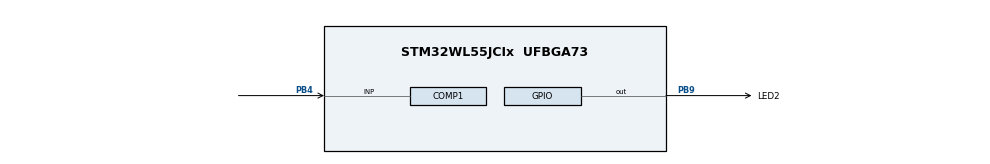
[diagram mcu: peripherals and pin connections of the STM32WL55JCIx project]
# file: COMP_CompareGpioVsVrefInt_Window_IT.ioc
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COMP1.BlankingSrce=COMP_BLANKINGSRC_NONE
COMP1.Hysteresis=COMP_HYSTERESIS_NONE
COMP1.Mode=COMP_POWERMODE_MEDIUMSPEED
COMP1.OutputPol=COMP_OUTPUTPOL_NONINVERTED
COMP1.TriggerMode=COMP_TRIGGERMODE_IT_RISING_FALLING
COMP2.BlankingSrce=COMP_BLANKINGSRC_NONE
COMP2.Hysteresis=COMP_HYSTERESIS_LOW
COMP2.Mode=COMP_POWERMODE_MEDIUMSPEED
COMP2.OutputPol=COMP_OUTPUTPOL_NONINVERTED
COMP2.TriggerMode=COMP_TRIGGERMODE_IT_RISING_FALLING
COMP2.WindowMode=COMP_WINDOWMODE_COMP1_INPUT_PLUS_COMMON
Mcu.Family=STM32WL
Mcu.Name=STM32WL55JCIx
Mcu.Package=UFBGA73
NVIC.COMP_IRQn=true\:0\:0\:false\:false\:true\:false\:true
NVIC.PriorityGroup=NVIC_PRIORITYGROUP_4
PB4.Mode=INP
PB4.Signal=COMP1_INP
PB9.GPIO_Label=LED2
PB9.Signal=GPIO_Output
ProjectManager.HeapSize=0x200
ProjectManager.StackSize=0x400
ProjectManager.TargetToolchain=EWARM V8
RCC.AHBFreq_Value=48000000
RCC.APB1Freq_Value=48000000
RCC.APB1TimFreq_Value=48000000
RCC.APB2Freq_Value=48000000
RCC.APB2TimFreq_Value=48000000
RCC.APB3Freq_Value=48000000
RCC.CortexFreq_Value=48000000
RCC.HCLKFreq_Value=48000000
RCC.HSE_VALUE=8000000
RCC.HSI_VALUE=16000000
RCC.LSE_VALUE=32768
RCC.MSIClockRange=RCC_MSIRANGE_11
RCC.SYSCLKFreq_VALUE=48000000
RCC.VCOOutputFreq_Value=384000000
VP_COMP1_VS_VREFINT.Mode=VREFINT
VP_COMP2_VS_VREFINT12.Mode=VREFINT_12
VP_COMP2_VS_WindowMode.Mode=WindowMode
board=custom

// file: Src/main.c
/* USER CODE BEGIN Header */
/**
  ******************************************************************************
  * @file    COMP/COMP_CompareGpioVsVrefInt_Window_IT/Src/main.c
  * @author  MCD Application Team
  * @brief   This example describes how to use a pair of comparator peripherals
  *          to compare a voltage level applied on a GPIO pin
  *          versus 2 thresholds, in interrupt mode.
  ******************************************************************************
  * @attention
  *
  * <h2><center>&copy; Copyright (c) 2020 STMicroelectronics.
  * All rights reserved.</center></h2>
  *
  * This software component is licensed by ST under BSD 3-Clause license,
  * the "License"; You may not use this file except in compliance with the
  * License. You may obtain a copy of the License at:
  *                        opensource.org/licenses/BSD-3-Clause
  *
  ******************************************************************************
  */
/* USER CODE END Header */
#include "main.h"

COMP_HandleTypeDef hcomp1;
COMP_HandleTypeDef hcomp2;

void SystemClock_Config(void);
static void MX_GPIO_Init(void);
static void MX_COMP1_Init(void);
static void MX_COMP2_Init(void);

int main(void)
{

  /* MCU Configuration--------------------------------------------------------*/

  /* Reset of all peripherals, Initializes the Flash interface and the Systick. */
  HAL_Init();

  /* Configure the system clock */
  SystemClock_Config();

  /* Initialize all configured peripherals */
  MX_GPIO_Init();
  MX_COMP1_Init();
  MX_COMP2_Init();
  /* USER CODE BEGIN 2 */

  /* Activate pair of comparators */
  /* Enable comparator instance master */
  if(HAL_COMP_Start(&hcomp1) != HAL_OK)
  {
    /* Initialization Error */
    Error_Handler();
  }
  /* Enable comparator instance slave */
  if(HAL_COMP_Start(&hcomp2) != HAL_OK)
  {
    /* Initialization Error */
    Error_Handler();
  }

  /* USER CODE END 2 */

  /* Infinite loop */
  /* USER CODE BEGIN WHILE */
  while (1)
  {
    /* Note: LED state depending on COMP status is set into COMP IRQ handler, */
    /*       refer to function "HAL_COMP_TriggerCallback()".                  */

    /* USER CODE END WHILE */

  }
}

void SystemClock_Config(void)
{
  RCC_OscInitTypeDef RCC_OscInitStruct = {0};
  RCC_ClkInitTypeDef RCC_ClkInitStruct = {0};

  /** Configure the main internal regulator output voltage
  */
  __HAL_PWR_VOLTAGESCALING_CONFIG(PWR_REGULATOR_VOLTAGE_SCALE1);
  /** Initializes the CPU, AHB and APB busses clocks
  */
  RCC_OscInitStruct.OscillatorType = RCC_OSCILLATORTYPE_MSI;
  RCC_OscInitStruct.MSIState = RCC_MSI_ON;
  RCC_OscInitStruct.MSICalibrationValue = RCC_MSICALIBRATION_DEFAULT;
  RCC_OscInitStruct.MSIClockRange = RCC_MSIRANGE_11;
  RCC_OscInitStruct.PLL.PLLState = RCC_PLL_NONE;
  if (HAL_RCC_OscConfig(&RCC_OscInitStruct) != HAL_OK)
  {
    Error_Handler();
  }
  /** Configure the SYSCLKSource, HCLK, PCLK1 and PCLK2 clocks dividers
  */
  RCC_ClkInitStruct.ClockType = RCC_CLOCKTYPE_HCLK3|RCC_CLOCKTYPE_HCLK
                              |RCC_CLOCKTYPE_SYSCLK|RCC_CLOCKTYPE_PCLK1
                              |RCC_CLOCKTYPE_PCLK2;
  RCC_ClkInitStruct.SYSCLKSource = RCC_SYSCLKSOURCE_MSI;
  RCC_ClkInitStruct.AHBCLKDivider = RCC_SYSCLK_DIV1;
  RCC_ClkInitStruct.APB1CLKDivider = RCC_HCLK_DIV1;
  RCC_ClkInitStruct.APB2CLKDivider = RCC_HCLK_DIV1;
  RCC_ClkInitStruct.AHBCLK3Divider = RCC_SYSCLK_DIV1;

  if (HAL_RCC_ClockConfig(&RCC_ClkInitStruct, FLASH_LATENCY_2) != HAL_OK)
  {
    Error_Handler();
  }
}

static void MX_COMP1_Init(void)
{

  hcomp1.Instance = COMP1;
  hcomp1.Init.InputMinus = COMP_INPUT_MINUS_VREFINT;
  hcomp1.Init.InputPlus = COMP_INPUT_PLUS_IO1;
  hcomp1.Init.OutputPol = COMP_OUTPUTPOL_NONINVERTED;
  hcomp1.Init.Hysteresis = COMP_HYSTERESIS_NONE;
  hcomp1.Init.BlankingSrce = COMP_BLANKINGSRC_NONE;
  hcomp1.Init.Mode = COMP_POWERMODE_MEDIUMSPEED;
  hcomp1.Init.WindowMode = COMP_WINDOWMODE_DISABLE;
  hcomp1.Init.TriggerMode = COMP_TRIGGERMODE_IT_RISING_FALLING;
  if (HAL_COMP_Init(&hcomp1) != HAL_OK)
  {
    Error_Handler();
  }

}

static void MX_COMP2_Init(void)
{

  hcomp2.Instance = COMP2;
  hcomp2.Init.InputMinus = COMP_INPUT_MINUS_1_2VREFINT;
  hcomp2.Init.InputPlus = COMP_INPUT_PLUS_IO1;
  hcomp2.Init.OutputPol = COMP_OUTPUTPOL_NONINVERTED;
  hcomp2.Init.Hysteresis = COMP_HYSTERESIS_LOW;
  hcomp2.Init.BlankingSrce = COMP_BLANKINGSRC_NONE;
  hcomp2.Init.Mode = COMP_POWERMODE_MEDIUMSPEED;
  hcomp2.Init.WindowMode = COMP_WINDOWMODE_COMP1_INPUT_PLUS_COMMON;
  hcomp2.Init.TriggerMode = COMP_TRIGGERMODE_IT_RISING_FALLING;
  if (HAL_COMP_Init(&hcomp2) != HAL_OK)
  {
    Error_Handler();
  }

}

static void MX_GPIO_Init(void)
{
  GPIO_InitTypeDef GPIO_InitStruct = {0};

  /* GPIO Ports Clock Enable */
  __HAL_RCC_GPIOB_CLK_ENABLE();

  /*Configure GPIO pin Output Level */
  HAL_GPIO_WritePin(LED2_GPIO_Port, LED2_Pin, GPIO_PIN_RESET);

  /*Configure GPIO pin : LED2_Pin */
  GPIO_InitStruct.Pin = LED2_Pin;
  GPIO_InitStruct.Mode = GPIO_MODE_OUTPUT_PP;
  GPIO_InitStruct.Pull = GPIO_NOPULL;
  GPIO_InitStruct.Speed = GPIO_SPEED_FREQ_LOW;
  HAL_GPIO_Init(LED2_GPIO_Port, &GPIO_InitStruct);

}

/* USER CODE BEGIN 4 */

/******************************************************************************/
/*   USER IRQ HANDLER TREATMENT                                               */
/******************************************************************************/

/**
  * @brief  Comparator trigger callback.
  * @param  hcomp  COMP handle
  * @retval None
  */
void HAL_COMP_TriggerCallback(COMP_HandleTypeDef *hcomp)
{
  __IO uint32_t COMP1OutputLevel = HAL_COMP_GetOutputLevel(&hcomp1);
  __IO uint32_t COMP2OutputLevel = HAL_COMP_GetOutputLevel(&hcomp2);

  /* Set LED state in function of comparator output level */
  /* Case of voltage above comparators thresholds window */
  if (   (COMP1OutputLevel == COMP_OUTPUT_LEVEL_LOW)
      && (COMP2OutputLevel == COMP_OUTPUT_LEVEL_LOW)
     )
  {
    BSP_LED_Off(LED2);
  }
  /* Case of voltage below comparators thresholds window */
  else if (   (COMP1OutputLevel == COMP_OUTPUT_LEVEL_HIGH)
           && (COMP2OutputLevel == COMP_OUTPUT_LEVEL_HIGH)
     )
  {
    BSP_LED_Off(LED2);
  }
  /* Case of voltage inside comparators thresholds window */
  else /* COMP1 output high, COMP2 output low */
  {
    BSP_LED_On(LED2);
  }
}

/* USER CODE END 4 */

void Error_Handler(void)
{
}

/************************ (C) COPYRIGHT STMicroelectronics *****END OF FILE****/
